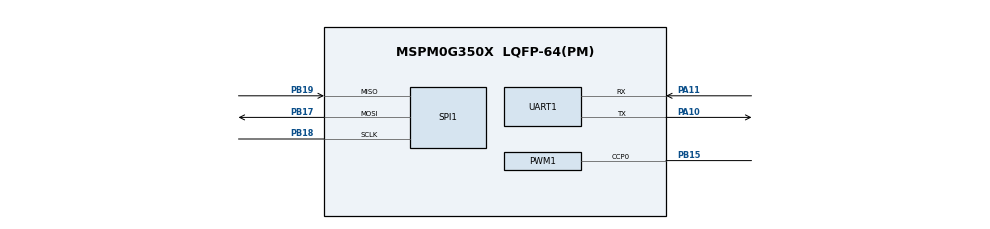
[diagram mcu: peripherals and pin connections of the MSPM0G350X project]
/**
 * @cliArgs --device "MSPM0G350X" --part "Default" --package "LQFP-64(PM)" --product "mspm0_sdk@2.06.00.05"
 * @versions {"tool":"1.21.0+3721"}
 */

/**
 * Import the modules used in this configuration.
 */
const ADC12         = scripting.addModule("/ti/driverlib/ADC12", {}, false);
const ADC121        = ADC12.addInstance();
const Board         = scripting.addModule("/ti/driverlib/Board");
const DAC12         = scripting.addModule("/ti/driverlib/DAC12");
const GPIO          = scripting.addModule("/ti/driverlib/GPIO", {}, false);
const GPIO1         = GPIO.addInstance();
const GPIO2         = GPIO.addInstance();
const GPIO3         = GPIO.addInstance();
const GPIO4         = GPIO.addInstance();
const PWM           = scripting.addModule("/ti/driverlib/PWM", {}, false);
const PWM1          = PWM.addInstance();
const SPI           = scripting.addModule("/ti/driverlib/SPI", {}, false);
const SPI1          = SPI.addInstance();
const SYSCTL        = scripting.addModule("/ti/driverlib/SYSCTL");
const TIMER         = scripting.addModule("/ti/driverlib/TIMER", {}, false);
const TIMER1        = TIMER.addInstance();
const TIMER2        = TIMER.addInstance();
const TIMER3        = TIMER.addInstance();
const UART          = scripting.addModule("/ti/driverlib/UART", {}, false);
const UART1         = UART.addInstance();
const ProjectConfig = scripting.addModule("/ti/project_config/ProjectConfig");

/**
 * Write custom configuration values to the imported modules.
 */
const gate8  = system.clockTree["MFPCLKGATE"];
gate8.enable = true;

const pinFunction4     = system.clockTree["HFXT"];
pinFunction4.inputFreq = 40;

ADC121.$name                      = "ADC12_0";
ADC121.sampClkSrc                 = "DL_ADC12_CLOCK_ULPCLK";
ADC121.sampClkDiv                 = "DL_ADC12_CLOCK_DIVIDE_8";
ADC121.powerDownMode              = "DL_ADC12_POWER_DOWN_MODE_MANUAL";
ADC121.samplingOperationMode      = "sequence";
ADC121.adcMem1chansel             = "DL_ADC12_INPUT_CHAN_2";
ADC121.adcMem1stime               = "DL_ADC12_SAMPLE_TIMER_SOURCE_SCOMP1";
ADC121.adcMem2chansel             = "DL_ADC12_INPUT_CHAN_2";
ADC121.adcMem3chansel             = "DL_ADC12_INPUT_CHAN_2";
ADC121.adcMem3stime               = "DL_ADC12_SAMPLE_TIMER_SOURCE_SCOMP1";
ADC121.sampleTime0                = "25 us";
ADC121.sampleTime1                = "12.5 us";
ADC121.subChanID                  = 1;
ADC121.trigSrc                    = "DL_ADC12_TRIG_SRC_EVENT";
ADC121.adcMem0chansel             = "DL_ADC12_INPUT_CHAN_3";
ADC121.enabledInterrupts          = ["DL_ADC12_INTERRUPT_MEM0_RESULT_LOADED"];
ADC121.repeatMode                 = true;
ADC121.adcMem0trig                = "DL_ADC12_TRIGGER_MODE_TRIGGER_NEXT";
ADC121.peripheral.$assign         = "ADC0";
ADC121.peripheral.adcPin3.$assign = "PA24";
ADC121.adcPin3Config.$name        = "ti_driverlib_gpio_GPIOPinGeneric0";


DAC12.sub0ChanID           = 2;
DAC12.dacFIFOEn            = true;
DAC12.dacFIFOTrigger       = "HWTRIG0";
DAC12.dacOutputPinEn       = true;
DAC12.dacSampleTimerEn     = false;
DAC12.dacAmplifier         = "ON";
DAC12.dacEnabledInterrupts = ["FIFO_TWO_QTRS_EMPTY"];
DAC12.OutPinConfig.$name   = "ti_driverlib_gpio_GPIOPinGeneric6";

GPIO1.$name                         = "BUTTON_PORTA";
GPIO1.port                          = "PORTA";
GPIO1.associatedPins[0].$name       = "S5";
GPIO1.associatedPins[0].direction   = "INPUT";
GPIO1.associatedPins[0].assignedPin = "18";

GPIO2.$name                          = "GPIO_LEDS";
GPIO2.associatedPins[0].$name        = "USER_TEST";
GPIO2.associatedPins[0].assignedPort = "PORTB";
GPIO2.associatedPins[0].assignedPin  = "16";

GPIO3.$name                          = "SPI1_GPIO";
GPIO3.port                           = "PORTB";
GPIO3.associatedPins[0].$name        = "CS";
GPIO3.associatedPins[0].initialValue = "SET";
GPIO3.associatedPins[0].ioStructure  = "SD";
GPIO3.associatedPins[0].assignedPin  = "20";

GPIO4.$name                               = "BUTTONS";
GPIO4.associatedPins.create(5);
GPIO4.associatedPins[0].$name             = "B_1";
GPIO4.associatedPins[0].direction         = "INPUT";
GPIO4.associatedPins[0].polarity          = "FALL";
GPIO4.associatedPins[0].interruptEn       = true;
GPIO4.associatedPins[0].interruptPriority = "1";
GPIO4.associatedPins[0].internalResistor  = "PULL_UP";
GPIO4.associatedPins[0].assignedPort      = "PORTB";
GPIO4.associatedPins[0].assignedPin       = "21";
GPIO4.associatedPins[1].$name             = "B_2";
GPIO4.associatedPins[1].direction         = "INPUT";
GPIO4.associatedPins[1].assignedPort      = "PORTB";
GPIO4.associatedPins[1].assignedPin       = "7";
GPIO4.associatedPins[1].polarity          = "FALL";
GPIO4.associatedPins[1].interruptEn       = true;
GPIO4.associatedPins[1].interruptPriority = "1";
GPIO4.associatedPins[1].internalResistor  = "PULL_UP";
GPIO4.associatedPins[2].$name             = "B_3";
GPIO4.associatedPins[2].direction         = "INPUT";
GPIO4.associatedPins[2].internalResistor  = "PULL_UP";
GPIO4.associatedPins[2].assignedPort      = "PORTB";
GPIO4.associatedPins[2].assignedPin       = "6";
GPIO4.associatedPins[2].interruptEn       = true;
GPIO4.associatedPins[2].interruptPriority = "1";
GPIO4.associatedPins[2].polarity          = "FALL";
GPIO4.associatedPins[3].$name             = "B_4";
GPIO4.associatedPins[3].direction         = "INPUT";
GPIO4.associatedPins[3].assignedPort      = "PORTB";
GPIO4.associatedPins[3].assignedPin       = "8";
GPIO4.associatedPins[3].interruptEn       = true;
GPIO4.associatedPins[3].interruptPriority = "1";
GPIO4.associatedPins[3].polarity          = "FALL";
GPIO4.associatedPins[3].internalResistor  = "PULL_UP";
GPIO4.associatedPins[4].$name             = "B_5";
GPIO4.associatedPins[4].direction         = "INPUT";
GPIO4.associatedPins[4].assignedPort      = "PORTB";
GPIO4.associatedPins[4].assignedPin       = "9";
GPIO4.associatedPins[4].interruptEn       = true;
GPIO4.associatedPins[4].interruptPriority = "1";
GPIO4.associatedPins[4].polarity          = "FALL";
GPIO4.associatedPins[4].internalResistor  = "PULL_UP";

PWM1.$name                              = "PWM_BUZZ";
PWM1.clockDivider                       = 2;
PWM1.timerCount                         = 60000;
PWM1.peripheral.$assign                 = "TIMG8";
PWM1.peripheral.ccp0Pin.$assign         = "PB15";
PWM1.PWM_CHANNEL_0.$name                = "ti_driverlib_pwm_PWMTimerCC0";
PWM1.PWM_CHANNEL_0.dutyCycle            = 0.2;
PWM1.PWM_CHANNEL_1.$name                = "ti_driverlib_pwm_PWMTimerCC1";
PWM1.ccp0PinConfig.direction            = scripting.forceWrite("OUTPUT");
PWM1.ccp0PinConfig.hideOutputInversion  = scripting.forceWrite(false);
PWM1.ccp0PinConfig.onlyInternalResistor = scripting.forceWrite(false);
PWM1.ccp0PinConfig.passedPeripheralType = scripting.forceWrite("Digital");
PWM1.ccp0PinConfig.$name                = "ti_driverlib_gpio_GPIOPinGeneric7";
PWM1.ccp1PinConfig.direction            = scripting.forceWrite("OUTPUT");
PWM1.ccp1PinConfig.hideOutputInversion  = scripting.forceWrite(false);
PWM1.ccp1PinConfig.onlyInternalResistor = scripting.forceWrite(false);
PWM1.ccp1PinConfig.passedPeripheralType = scripting.forceWrite("Digital");
PWM1.ccp1PinConfig.$name                = "ti_driverlib_gpio_GPIOPinGeneric8";

SPI1.$name                              = "SPI1";
SPI1.targetBitRate                      = 500000;
SPI1.frameFormat                        = "MOTO3";
SPI1.peripheral.sclkPin.$assign         = "PB18";
SPI1.peripheral.mosiPin.$assign         = "PB17";
SPI1.peripheral.misoPin.$assign         = "PB19";
SPI1.sclkPinConfig.$name                = "ti_driverlib_gpio_GPIOPinGeneric3";
SPI1.sclkPinConfig.direction            = scripting.forceWrite("OUTPUT");
SPI1.sclkPinConfig.onlyInternalResistor = scripting.forceWrite(false);
SPI1.sclkPinConfig.passedPeripheralType = scripting.forceWrite("Digital");
SPI1.mosiPinConfig.$name                = "ti_driverlib_gpio_GPIOPinGeneric4";
SPI1.mosiPinConfig.direction            = scripting.forceWrite("OUTPUT");
SPI1.mosiPinConfig.hideOutputInversion  = scripting.forceWrite(false);
SPI1.mosiPinConfig.onlyInternalResistor = scripting.forceWrite(false);
SPI1.mosiPinConfig.passedPeripheralType = scripting.forceWrite("Digital");
SPI1.misoPinConfig.$name                = "ti_driverlib_gpio_GPIOPinGeneric5";
SPI1.misoPinConfig.onlyInternalResistor = scripting.forceWrite(false);
SPI1.misoPinConfig.passedPeripheralType = scripting.forceWrite("Digital");

SYSCTL.forceDefaultClkConfig = true;
SYSCTL.clockTreeEn           = true;

TIMER1.$name                       = "TIMER_0";
TIMER1.event1PublisherChannel      = 1;
TIMER1.event1ControllerInterruptEn = ["ZERO_EVENT"];
TIMER1.timerMode                   = "PERIODIC";
TIMER1.timerClkPrescale            = 32;
TIMER1.timerPeriod                 = "100 us";
TIMER1.peripheral.$assign          = "TIMG0";

TIMER2.$name              = "TIMER_1";
TIMER2.timerPeriod        = "1 ms";
TIMER2.timerStartTimer    = true;
TIMER2.enableShadowLoad   = true;
TIMER2.interrupts         = ["LOAD"];
TIMER2.timerMode          = "PERIODIC";
TIMER2.peripheral.$assign = "TIMG7";

TIMER3.$name                       = "TIMER_2";
TIMER3.event1PublisherChannel      = 2;
TIMER3.timerClkDiv                 = 8;
TIMER3.timerPeriod                 = "10us";
TIMER3.event1ControllerInterruptEn = ["ZERO_EVENT"];
TIMER3.timerMode                   = "PERIODIC";
TIMER3.peripheral.$assign          = "TIMG6";

UART1.$name                    = "UART_0";
UART1.enabledInterrupts        = ["RX"];
UART1.peripheral.rxPin.$assign = "PA11";
UART1.peripheral.txPin.$assign = "PA10";
UART1.txPinConfig.$name        = "ti_driverlib_gpio_GPIOPinGeneric1";
UART1.rxPinConfig.$name        = "ti_driverlib_gpio_GPIOPinGeneric2";

ProjectConfig.genLibCMSIS = true;

/**
 * Pinmux solution for unlocked pins/peripherals. This ensures that minor changes to the automatic solver in a future
 * version of the tool will not impact the pinmux you originally saw.  These lines can be completely deleted in order to
 * re-solve from scratch.
 */
Board.peripheral.$suggestSolution            = "DEBUGSS";
Board.peripheral.swclkPin.$suggestSolution   = "PA20";
Board.peripheral.swdioPin.$suggestSolution   = "PA19";
DAC12.peripheral.$suggestSolution            = "DAC0";
DAC12.peripheral.OutPin.$suggestSolution     = "PA15";
GPIO1.associatedPins[0].pin.$suggestSolution = "PA18";
GPIO2.associatedPins[0].pin.$suggestSolution = "PB16";
GPIO3.associatedPins[0].pin.$suggestSolution = "PB20";
GPIO4.associatedPins[0].pin.$suggestSolution = "PB21";
GPIO4.associatedPins[1].pin.$suggestSolution = "PB7";
GPIO4.associatedPins[2].pin.$suggestSolution = "PB6";
GPIO4.associatedPins[3].pin.$suggestSolution = "PB8";
GPIO4.associatedPins[4].pin.$suggestSolution = "PB9";
PWM1.peripheral.ccp1Pin.$suggestSolution     = "PA0";
SPI1.peripheral.$suggestSolution             = "SPI0";
UART1.peripheral.$suggestSolution            = "UART0";
